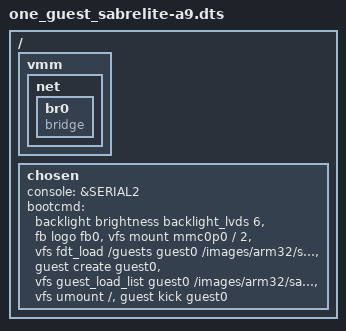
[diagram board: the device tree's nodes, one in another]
/*
 * Copyright (C) 2014 Institut de Recherche Technologique SystemX and OpenWide.
 * Originally from Jean-Christophe Dubois, and modified by
 * Jimmy Durand Wesolowski (jimmy.durand-wesolowski@openwide.fr)
 * to split device tree files between i.MX6-specific and Sabrelite-specific
 * definitions.
 */

/dts-v1/;

#include "sabrelite-a9.dtsi"

/ {
	vmm {
		net {
			br0 {
				device_type = "netswitch";
				compatible = "bridge";
			};
		};
	};

	chosen {
		console = &SERIAL2;
		bootcmd =
			"backlight brightness backlight_lvds 6",
			"fb logo fb0",

			/* Mount SD device */
			"vfs mount mmc0p0 / 2",

			/* Load guest0 device tree from file */
			"vfs fdt_load /guests guest0 /images/arm32/sabrelite-a9.dtb mem0,physical_size,physsize,0x06000000 net0,switch,string,br0",

			/* Create guest0 */
			"guest create guest0",

			/* Load guest0 images */
			"vfs guest_load_list guest0 /images/arm32/sabrelite-a9/nor_flash.list",

			/* Umount the SD/MMC card */
			"vfs umount /",

			/* Kick the guest */
			"guest kick guest0";
	};
};
